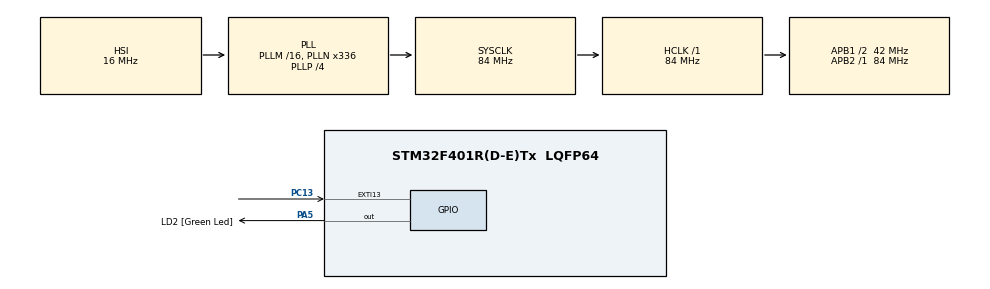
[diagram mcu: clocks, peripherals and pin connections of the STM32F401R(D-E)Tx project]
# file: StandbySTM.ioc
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FREERTOS.Tasks01=defaultTask,0,128,StartDefaultTask
Mcu.Family=STM32F4
Mcu.Name=STM32F401R(D-E)Tx
Mcu.Package=LQFP64
NVIC.EXTI15_10_IRQn=true\:5\:0\:false\:false\:true\:true
NVIC.PriorityGroup=NVIC_PRIORITYGROUP_4
NVIC.RTC_WKUP_IRQn=true\:5\:0\:false\:false\:true\:true
NVIC.TIM1_UP_TIM10_IRQn=true\:0\:0\:false\:false\:true\:false
NVIC.TimeBase=TIM1_UP_TIM10_IRQn
NVIC.TimeBaseIP=TIM1
PA0-WKUP.Mode=SYS_WakeUp0
PA0-WKUP.Signal=SYS_WKUP
PA13.GPIO_Label=TMS
PA13.Mode=Trace_Asynchronous_SW
PA13.Signal=SYS_JTMS-SWDIO
PA14.GPIO_Label=TCK
PA14.Mode=Trace_Asynchronous_SW
PA14.Signal=SYS_JTCK-SWCLK
PA2.GPIO_Label=USART_TX
PA2.GPIO_Mode=GPIO_MODE_AF_PP
PA2.GPIO_PuPd=GPIO_NOPULL
PA2.GPIO_Speed=GPIO_SPEED_FREQ_LOW
PA2.Signal=USART2_TX
PA3.GPIO_Label=USART_RX
PA3.GPIO_Mode=GPIO_MODE_AF_PP
PA3.GPIO_PuPd=GPIO_NOPULL
PA3.GPIO_Speed=GPIO_SPEED_FREQ_LOW
PA3.Signal=USART2_RX
PA5.GPIO_Label=LD2 [Green Led]
PA5.GPIO_Mode=GPIO_MODE_OUTPUT_PP
PA5.GPIO_PuPd=GPIO_NOPULL
PA5.GPIO_Speed=GPIO_SPEED_FREQ_LOW
PA5.Signal=GPIO_Output
PB3.GPIO_Label=SWO
PB3.Mode=Trace_Asynchronous_SW
PB3.Signal=SYS_JTDO-SWO
PC13-ANTI_TAMP.Signal=GPXTI13
PC14-OSC32_IN.Signal=RCC_OSC32_IN
PC15-OSC32_OUT.Signal=RCC_OSC32_OUT
PH0\ -\ OSC_IN.Signal=RCC_OSC_IN
PH1\ -\ OSC_OUT.Signal=RCC_OSC_OUT
ProjectManager.HeapSize=0x200
ProjectManager.StackSize=0x400
ProjectManager.TargetToolchain=SW4STM32
RCC.AHBFreq_Value=84000000
RCC.APB1CLKDivider=RCC_HCLK_DIV2
RCC.APB1Freq_Value=42000000
RCC.APB1TimFreq_Value=84000000
RCC.APB2Freq_Value=84000000
RCC.APB2TimFreq_Value=84000000
RCC.CortexFreq_Value=84000000
RCC.HCLKFreq_Value=84000000
RCC.HSE_VALUE=8000000
RCC.HSI_VALUE=16000000
RCC.LSE_VALUE=32768
RCC.PLLN=336
RCC.PLLP=RCC_PLLP_DIV4
RCC.PLLQ=7
RCC.SYSCLKFreq_VALUE=84000000
RCC.SYSCLKSource=RCC_SYSCLKSOURCE_PLLCLK
RCC.VCOOutputFreq_Value=336000000
VP_FREERTOS_VS_ENABLE.Mode=Enabled
VP_RTC_VS_RTC_WakeUp_intern.Mode=WakeUp
VP_SYS_VS_tim1.Mode=TIM1
board=NUCLEO-F401RE

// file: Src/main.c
/**
  ******************************************************************************
  * File Name          : main.c
  * Description        : Main program body
  ******************************************************************************
  *
  * COPYRIGHT(c) 2015 STMicroelectronics
  *
  * Redistribution and use in source and binary forms, with or without modification,
  * are permitted provided that the following conditions are met:
  *   1. Redistributions of source code must retain the above copyright notice,
  *      this list of conditions and the following disclaimer.
  *   2. Redistributions in binary form must reproduce the above copyright notice,
  *      this list of conditions and the following disclaimer in the documentation
  *      and/or other materials provided with the distribution.
  *   3. Neither the name of STMicroelectronics nor the names of its contributors
  *      may be used to endorse or promote products derived from this software
  *      without specific prior written permission.
  *
  * THIS SOFTWARE IS PROVIDED BY THE COPYRIGHT HOLDERS AND CONTRIBUTORS "AS IS"
  * AND ANY EXPRESS OR IMPLIED WARRANTIES, INCLUDING, BUT NOT LIMITED TO, THE
  * IMPLIED WARRANTIES OF MERCHANTABILITY AND FITNESS FOR A PARTICULAR PURPOSE ARE
  * DISCLAIMED. IN NO EVENT SHALL THE COPYRIGHT HOLDER OR CONTRIBUTORS BE LIABLE
  * FOR ANY DIRECT, INDIRECT, INCIDENTAL, SPECIAL, EXEMPLARY, OR CONSEQUENTIAL
  * DAMAGES (INCLUDING, BUT NOT LIMITED TO, PROCUREMENT OF SUBSTITUTE GOODS OR
  * SERVICES; LOSS OF USE, DATA, OR PROFITS; OR BUSINESS INTERRUPTION) HOWEVER
  * CAUSED AND ON ANY THEORY OF LIABILITY, WHETHER IN CONTRACT, STRICT LIABILITY,
  * OR TORT (INCLUDING NEGLIGENCE OR OTHERWISE) ARISING IN ANY WAY OUT OF THE USE
  * OF THIS SOFTWARE, EVEN IF ADVISED OF THE POSSIBILITY OF SUCH DAMAGE.
  *
  ******************************************************************************
  */
#include "stm32f4xx_hal.h"
#include "cmsis_os.h"
#include "rtc.h"
#include "gpio.h"

/* USER CODE BEGIN PV */
/* Private variables ---------------------------------------------------------*/

/* USER CODE END PV */

void SystemClock_Config(void);
void MX_FREERTOS_Init(void);

/* USER CODE BEGIN PFP */
/* Private function prototypes -----------------------------------------------*/

/* USER CODE END PFP */

int main(void)
{

  /* USER CODE BEGIN 1 */
  RTC_TimeTypeDef sTime;

  /* USER CODE END 1 */

  /* MCU Configuration----------------------------------------------------------*/

  /* Reset of all peripherals, Initializes the Flash interface and the Systick. */
  HAL_Init();

  /* Configure the system clock */
  SystemClock_Config();

  __HAL_PWR_CLEAR_FLAG(PWR_FLAG_WU);
  while((PWR->CSR & (uint32_t) 0x00000001)!=0);//attesa che il WUF si azzeri (via HW)

  /* Initialize all configured peripherals */
  MX_GPIO_Init();
  MX_RTC_Init();

  HAL_RTCEx_DeactivateWakeUpTimer(&hrtc);

  /* USER CODE BEGIN 2 */
//  if (sTime.Minutes > 1) {
//
//	HAL_GPIO_TogglePin(GPIOA, GPIO_PIN_5);
//	HAL_Delay(3000);
//	HAL_GPIO_TogglePin(GPIOA, GPIO_PIN_5);
//  }
  /* USER CODE END 2 */

  /* Call init function for freertos objects (in freertos.c) */
  MX_FREERTOS_Init();

  /* Start scheduler */
  osKernelStart();

  /* We should never get here as control is now taken by the scheduler */

  /* Infinite loop */
  while (1)
  {

  }

}

/** System Clock Configuration
*/
void SystemClock_Config(void)
{

  RCC_OscInitTypeDef RCC_OscInitStruct;
  RCC_ClkInitTypeDef RCC_ClkInitStruct;
  RCC_PeriphCLKInitTypeDef PeriphClkInitStruct;

  __PWR_CLK_ENABLE();

  __HAL_PWR_VOLTAGESCALING_CONFIG(PWR_REGULATOR_VOLTAGE_SCALE1);

  RCC_OscInitStruct.OscillatorType = RCC_OSCILLATORTYPE_HSI|RCC_OSCILLATORTYPE_LSI;
  RCC_OscInitStruct.HSIState = RCC_HSI_ON;
  RCC_OscInitStruct.HSICalibrationValue = 16;
  RCC_OscInitStruct.LSIState = RCC_LSI_ON;
  RCC_OscInitStruct.PLL.PLLState = RCC_PLL_ON;
  RCC_OscInitStruct.PLL.PLLSource = RCC_PLLSOURCE_HSI;
  RCC_OscInitStruct.PLL.PLLM = 16;
  RCC_OscInitStruct.PLL.PLLN = 336;
  RCC_OscInitStruct.PLL.PLLP = RCC_PLLP_DIV4;
  RCC_OscInitStruct.PLL.PLLQ = 7;
  HAL_RCC_OscConfig(&RCC_OscInitStruct);

  RCC_ClkInitStruct.ClockType = RCC_CLOCKTYPE_SYSCLK|RCC_CLOCKTYPE_PCLK1;
  RCC_ClkInitStruct.SYSCLKSource = RCC_SYSCLKSOURCE_PLLCLK;
  RCC_ClkInitStruct.AHBCLKDivider = RCC_SYSCLK_DIV1;
  RCC_ClkInitStruct.APB1CLKDivider = RCC_HCLK_DIV2;
  RCC_ClkInitStruct.APB2CLKDivider = RCC_HCLK_DIV1;
  HAL_RCC_ClockConfig(&RCC_ClkInitStruct, FLASH_LATENCY_2);

  PeriphClkInitStruct.PeriphClockSelection = RCC_PERIPHCLK_RTC;
  PeriphClkInitStruct.RTCClockSelection = RCC_RTCCLKSOURCE_LSI;
  HAL_RCCEx_PeriphCLKConfig(&PeriphClkInitStruct);

  HAL_SYSTICK_Config(HAL_RCC_GetHCLKFreq()/1000);

  HAL_SYSTICK_CLKSourceConfig(SYSTICK_CLKSOURCE_HCLK);

  /* SysTick_IRQn interrupt configuration */
  HAL_NVIC_SetPriority(SysTick_IRQn, 0, 0);
}

/************************ (C) COPYRIGHT STMicroelectronics *****END OF FILE****/

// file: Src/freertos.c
/**
  ******************************************************************************
  * File Name          : freertos.c
  * Description        : Code for freertos applications
  ******************************************************************************
  *
  * COPYRIGHT(c) 2015 STMicroelectronics
  *
  * Redistribution and use in source and binary forms, with or without modification,
  * are permitted provided that the following conditions are met:
  *   1. Redistributions of source code must retain the above copyright notice,
  *      this list of conditions and the following disclaimer.
  *   2. Redistributions in binary form must reproduce the above copyright notice,
  *      this list of conditions and the following disclaimer in the documentation
  *      and/or other materials provided with the distribution.
  *   3. Neither the name of STMicroelectronics nor the names of its contributors
  *      may be used to endorse or promote products derived from this software
  *      without specific prior written permission.
  *
  * THIS SOFTWARE IS PROVIDED BY THE COPYRIGHT HOLDERS AND CONTRIBUTORS "AS IS"
  * AND ANY EXPRESS OR IMPLIED WARRANTIES, INCLUDING, BUT NOT LIMITED TO, THE
  * IMPLIED WARRANTIES OF MERCHANTABILITY AND FITNESS FOR A PARTICULAR PURPOSE ARE
  * DISCLAIMED. IN NO EVENT SHALL THE COPYRIGHT HOLDER OR CONTRIBUTORS BE LIABLE
  * FOR ANY DIRECT, INDIRECT, INCIDENTAL, SPECIAL, EXEMPLARY, OR CONSEQUENTIAL
  * DAMAGES (INCLUDING, BUT NOT LIMITED TO, PROCUREMENT OF SUBSTITUTE GOODS OR
  * SERVICES; LOSS OF USE, DATA, OR PROFITS; OR BUSINESS INTERRUPTION) HOWEVER
  * CAUSED AND ON ANY THEORY OF LIABILITY, WHETHER IN CONTRACT, STRICT LIABILITY,
  * OR TORT (INCLUDING NEGLIGENCE OR OTHERWISE) ARISING IN ANY WAY OUT OF THE USE
  * OF THIS SOFTWARE, EVEN IF ADVISED OF THE POSSIBILITY OF SUCH DAMAGE.
  *
  ******************************************************************************
  */

#include "FreeRTOS.h"
#include "task.h"
#include "cmsis_os.h"

/* USER CODE BEGIN Includes */
#include "gpio.h"
#include "rtc.h"
/* USER CODE END Includes */

osThreadId defaultTaskHandle;

void StartDefaultTask(void const * argument);

void MX_FREERTOS_Init(void); /* (MISRA C 2004 rule 8.1) */

/* Hook prototypes */

/* Init FreeRTOS */

void MX_FREERTOS_Init(void) {

  /* Create the thread(s) */
  /* definition and creation of defaultTask */
  osThreadDef(defaultTask, StartDefaultTask, osPriorityNormal, 0, 128);
  defaultTaskHandle = osThreadCreate(osThread(defaultTask), NULL);

}

/* StartDefaultTask function */
void StartDefaultTask(void const * argument)
{
  int i = 1;
  /* USER CODE BEGIN StartDefaultTask */
  /* Infinite loop */
  for(;;)
  {
	  if ((i % 64) == 0)
	  {
		  __HAL_PWR_CLEAR_FLAG(PWR_FLAG_WU);
		  while((PWR->CSR & (uint32_t) 0x00000001)!=0);//attesa che il WUF si azzeri (via HW)

		  HAL_RTCEx_SetWakeUpTimer_IT(&hrtc, 16384, RTC_WAKEUPCLOCK_RTCCLK_DIV16);

		  HAL_PWR_EnableWakeUpPin(PWR_WAKEUP_PIN1);
		  HAL_PWR_EnterSTANDBYMode();
	  }
	  HAL_GPIO_TogglePin(GPIOA, GPIO_PIN_5);
	  osDelay(100);
	  i++;
  }
  /* USER CODE END StartDefaultTask */
}

/************************ (C) COPYRIGHT STMicroelectronics *****END OF FILE****/
